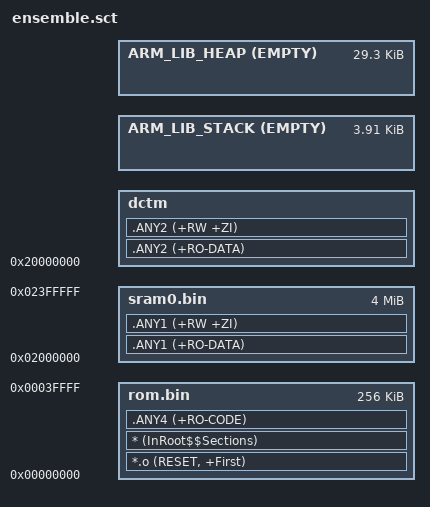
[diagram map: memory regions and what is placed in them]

; *************************************************************
; ***       Scatter-Loading Description File                ***
; *************************************************************

LOAD_REGION_ITCM       0x00000000                  0x00040000
{
    ;-----------------------------------------------------
    ; Code region
    ;-----------------------------------------------------
    rom.bin         0x00000000                  0x00040000
    {
        *.o (RESET, +First)
        * (InRoot$$Sections)
        .ANY4 (+RO-CODE) ;  ANY4 means map here first
    }
}

LOAD_REGION_DTCM       0x20000000                  0x100000 ;1MB
{
    ; max ANY is what's left after stack and heap
    dctm          +0 ANY_SIZE (0x100000-4000-30000) ALIGN 16
    {
        .ANY2 (+RO-DATA) ; ANY2 means map here first
        .ANY2 (+RW +ZI)
    }
    
    ; these have to come at the end b/c they don't take up load region space
    ARM_LIB_STACK +0 EMPTY ALIGN 8      4000
    {}

    ARM_LIB_HEAP  +0 EMPTY ALIGN 8      30000
    {}
}

LOAD_REGION_SRAM    0x02000000                  0x00400000
{ 
    sram0.bin       0x02000000 ALIGN 16         0x00400000
    {
        ; Uncomment these to place model in SRAM, in case of a large model (image, etc)
        ; main.o(*trained_tflite)
        ; TODO: EON
        .ANY1 (+RO-DATA)
        .ANY1 (+RW +ZI)
    }
}
